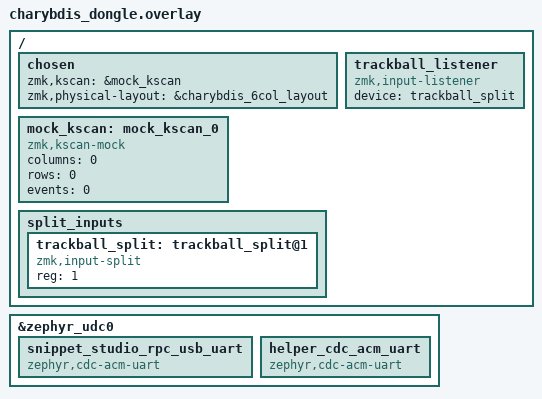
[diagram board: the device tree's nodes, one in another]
/*
 * Copyright (c) 2026 The ZMK Contributors
 * SPDX-License-Identifier: MIT
 *
 * Central Wireless Dongle — принимает по BLE обе половины (charybdis_left + charybdis_right_dongle)
 * и поток трекбола (trackball_split@0), обрабатывает слои, Auto-Mouse, Scroll, Snipe и ZMK Studio.
 * Совместим с любой BLE-платой ZMK (nice_nano//zmk, xiao_ble//zmk и др.).
 */

#include "charybdis-layouts.dtsi"

/ {
    chosen {
        zmk,kscan = &mock_kscan;
        zmk,physical-layout = &charybdis_6col_layout;
    };

    mock_kscan: mock_kscan_0 {
        compatible = "zmk,kscan-mock";
        columns = <0>;
        rows = <0>;
        events = <0>;
    };

    /* ВАЖНО: reg = <1> обязан совпадать с charybdis_pmw3610.dtsi и быть ненулевым (см. central.c:90) */
    split_inputs {
        #address-cells = <1>;
        #size-cells = <0>;

        trackball_split: trackball_split@1 {
            compatible = "zmk,input-split";
            reg = <1>;
            status = "okay";
        };
    };

    trackball_listener: trackball_listener {
        compatible = "zmk,input-listener";
        device = <&trackball_split>;
        status = "okay";
    };
};

/*
 * Два независимых виртуальных USB CDC-ACM порта:
 *   MI_00 (первый) = snippet_studio_rpc_usb_uart -> эксклюзивно для ZMK Studio (COM8)
 *   MI_02 (второй) = helper_cdc_acm_uart         -> мост управления и телеметрии Charybdis Helper
 */
&zephyr_udc0 {
    snippet_studio_rpc_usb_uart: snippet_studio_rpc_usb_uart {
        compatible = "zephyr,cdc-acm-uart";
    };

    helper_cdc_acm_uart: helper_cdc_acm_uart {
        compatible = "zephyr,cdc-acm-uart";
    };
};
